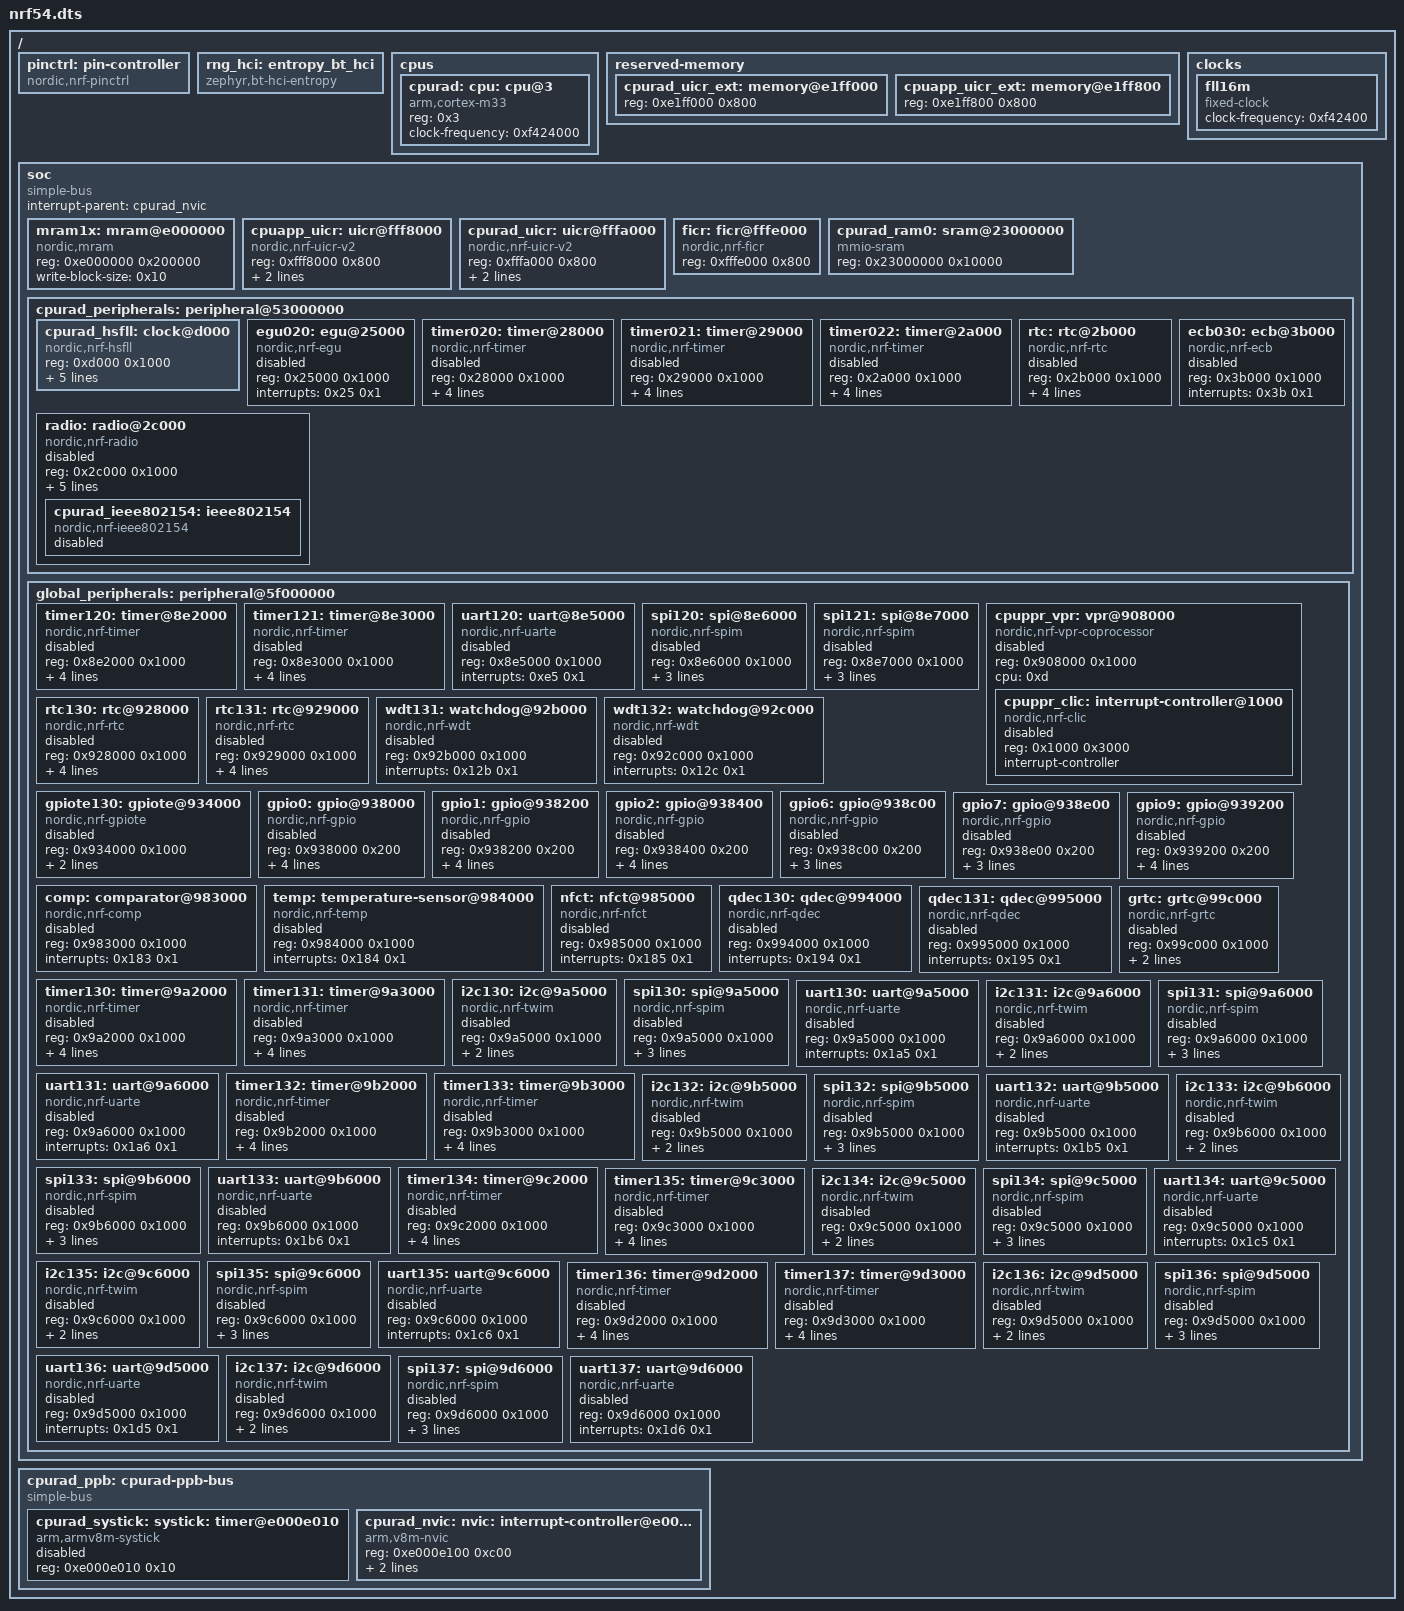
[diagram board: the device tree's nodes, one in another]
/dts-v1/;

/ {
	#address-cells = < 0x1 >;
	#size-cells = < 0x1 >;
	pinctrl: pin-controller {
		compatible = "nordic,nrf-pinctrl";
	};
	rng_hci: entropy_bt_hci {
		compatible = "zephyr,bt-hci-entropy";
		status = "okay";
	};
	cpus {
		#address-cells = < 0x1 >;
		#size-cells = < 0x0 >;
		cpurad: cpu: cpu@3 {
			compatible = "arm,cortex-m33";
			reg = < 0x3 >;
			device_type = "cpu";
			clock-frequency = < 0xf424000 >;
		};
	};
	reserved-memory {
		#address-cells = < 0x1 >;
		#size-cells = < 0x1 >;
		cpurad_uicr_ext: memory@e1ff000 {
			reg = < 0xe1ff000 0x800 >;
			phandle = < 0x3 >;
		};
		cpuapp_uicr_ext: memory@e1ff800 {
			reg = < 0xe1ff800 0x800 >;
			phandle = < 0x2 >;
		};
	};
	clocks {
		fll16m: fll16m {
			compatible = "fixed-clock";
			#clock-cells = < 0x0 >;
			clock-frequency = < 0xf42400 >;
			phandle = < 0x4 >;
		};
	};
	soc {
		#address-cells = < 0x1 >;
		#size-cells = < 0x1 >;
		compatible = "simple-bus";
		interrupt-parent = < &cpurad_nvic >;
		ranges;
		mram1x: mram@e000000 {
			compatible = "nordic,mram";
			reg = < 0xe000000 0x200000 >;
			write-block-size = < 0x10 >;
		};
		cpuapp_uicr: uicr@fff8000 {
			compatible = "nordic,nrf-uicr-v2";
			reg = < 0xfff8000 0x800 >;
			domain = < 0x2 >;
			ptr-ext-uicr = < &cpuapp_uicr_ext >;
		};
		cpurad_uicr: uicr@fffa000 {
			compatible = "nordic,nrf-uicr-v2";
			reg = < 0xfffa000 0x800 >;
			domain = < 0x3 >;
			ptr-ext-uicr = < &cpurad_uicr_ext >;
		};
		ficr: ficr@fffe000 {
			compatible = "nordic,nrf-ficr";
			reg = < 0xfffe000 0x800 >;
			#nordic,ficr-cells = < 0x1 >;
			phandle = < 0x5 >;
		};
		cpurad_ram0: sram@23000000 {
			compatible = "mmio-sram";
			reg = < 0x23000000 0x10000 >;
			#address-cells = < 0x1 >;
			#size-cells = < 0x1 >;
			ranges = < 0x0 0x23000000 0x10000 >;
		};
		cpurad_peripherals: peripheral@53000000 {
			#address-cells = < 0x1 >;
			#size-cells = < 0x1 >;
			ranges = < 0x0 0x53000000 0x1000000 >;
			cpurad_hsfll: clock@d000 {
				compatible = "nordic,nrf-hsfll";
				#clock-cells = < 0x0 >;
				reg = < 0xd000 0x1000 >;
				clocks = < &fll16m >;
				clock-frequency = < 0xf424000 >;
				nordic,ficrs = < &ficr 0x418 >, < &ficr 0x420 >, < &ficr 0x438 >;
				nordic,ficr-names = "vsup", "coarse", "fine";
			};
			egu020: egu@25000 {
				compatible = "nordic,nrf-egu";
				reg = < 0x25000 0x1000 >;
				status = "disabled";
				interrupts = < 0x25 0x1 >;
			};
			timer020: timer@28000 {
				compatible = "nordic,nrf-timer";
				reg = < 0x28000 0x1000 >;
				status = "disabled";
				cc-num = < 0x8 >;
				interrupts = < 0x28 0x1 >;
				max-bit-width = < 0x20 >;
				prescaler = < 0x0 >;
			};
			timer021: timer@29000 {
				compatible = "nordic,nrf-timer";
				reg = < 0x29000 0x1000 >;
				status = "disabled";
				cc-num = < 0x8 >;
				interrupts = < 0x29 0x1 >;
				max-bit-width = < 0x20 >;
				prescaler = < 0x0 >;
			};
			timer022: timer@2a000 {
				compatible = "nordic,nrf-timer";
				reg = < 0x2a000 0x1000 >;
				status = "disabled";
				cc-num = < 0x8 >;
				interrupts = < 0x2a 0x1 >;
				max-bit-width = < 0x20 >;
				prescaler = < 0x0 >;
			};
			rtc: rtc@2b000 {
				compatible = "nordic,nrf-rtc";
				reg = < 0x2b000 0x1000 >;
				status = "disabled";
				cc-num = < 0x4 >;
				clock-frequency = < 0x8000 >;
				interrupts = < 0x2b 0x1 >;
				prescaler = < 0x1 >;
			};
			radio: radio@2c000 {
				compatible = "nordic,nrf-radio";
				reg = < 0x2c000 0x1000 >;
				status = "disabled";
				ble-2mbps-supported;
				ble-coded-phy-supported;
				dfe-supported;
				ieee802154-supported;
				interrupts = < 0x2c 0x1 >;
				cpurad_ieee802154: ieee802154 {
					compatible = "nordic,nrf-ieee802154";
					status = "disabled";
				};
			};
			ecb030: ecb@3b000 {
				compatible = "nordic,nrf-ecb";
				reg = < 0x3b000 0x1000 >;
				interrupts = < 0x3b 0x1 >;
				status = "disabled";
			};
		};
		global_peripherals: peripheral@5f000000 {
			#address-cells = < 0x1 >;
			#size-cells = < 0x1 >;
			ranges = < 0x0 0x5f000000 0x1000000 >;
			timer120: timer@8e2000 {
				compatible = "nordic,nrf-timer";
				reg = < 0x8e2000 0x1000 >;
				status = "disabled";
				cc-num = < 0x6 >;
				interrupts = < 0xe2 0x1 >;
				max-bit-width = < 0x20 >;
				prescaler = < 0x0 >;
			};
			timer121: timer@8e3000 {
				compatible = "nordic,nrf-timer";
				reg = < 0x8e3000 0x1000 >;
				status = "disabled";
				cc-num = < 0x6 >;
				interrupts = < 0xe3 0x1 >;
				max-bit-width = < 0x20 >;
				prescaler = < 0x0 >;
			};
			uart120: uart@8e5000 {
				compatible = "nordic,nrf-uarte";
				reg = < 0x8e5000 0x1000 >;
				status = "disabled";
				interrupts = < 0xe5 0x1 >;
			};
			spi120: spi@8e6000 {
				compatible = "nordic,nrf-spim";
				reg = < 0x8e6000 0x1000 >;
				status = "disabled";
				easydma-maxcnt-bits = < 0xf >;
				interrupts = < 0xe6 0x1 >;
				max-frequency = < 0x1e84800 >;
				#address-cells = < 0x1 >;
				#size-cells = < 0x0 >;
			};
			spi121: spi@8e7000 {
				compatible = "nordic,nrf-spim";
				reg = < 0x8e7000 0x1000 >;
				status = "disabled";
				easydma-maxcnt-bits = < 0xf >;
				interrupts = < 0xe7 0x1 >;
				max-frequency = < 0x1e84800 >;
				#address-cells = < 0x1 >;
				#size-cells = < 0x0 >;
			};
			cpuppr_vpr: vpr@908000 {
				compatible = "nordic,nrf-vpr-coprocessor";
				reg = < 0x908000 0x1000 >;
				status = "disabled";
				cpu = < 0xd >;
				#address-cells = < 0x1 >;
				#size-cells = < 0x1 >;
				ranges = < 0x0 0x908000 0x4000 >;
				cpuppr_clic: interrupt-controller@1000 {
					compatible = "nordic,nrf-clic";
					reg = < 0x1000 0x3000 >;
					status = "disabled";
					#interrupt-cells = < 0x2 >;
					interrupt-controller;
					#address-cells = < 0x1 >;
				};
			};
			rtc130: rtc@928000 {
				compatible = "nordic,nrf-rtc";
				reg = < 0x928000 0x1000 >;
				status = "disabled";
				cc-num = < 0x4 >;
				clock-frequency = < 0x8000 >;
				interrupts = < 0x128 0x1 >;
				prescaler = < 0x1 >;
			};
			rtc131: rtc@929000 {
				compatible = "nordic,nrf-rtc";
				reg = < 0x929000 0x1000 >;
				status = "disabled";
				cc-num = < 0x4 >;
				clock-frequency = < 0x8000 >;
				interrupts = < 0x129 0x1 >;
				prescaler = < 0x1 >;
			};
			wdt131: watchdog@92b000 {
				compatible = "nordic,nrf-wdt";
				reg = < 0x92b000 0x1000 >;
				status = "disabled";
				interrupts = < 0x12b 0x1 >;
			};
			wdt132: watchdog@92c000 {
				compatible = "nordic,nrf-wdt";
				reg = < 0x92c000 0x1000 >;
				status = "disabled";
				interrupts = < 0x12c 0x1 >;
			};
			gpiote130: gpiote@934000 {
				compatible = "nordic,nrf-gpiote";
				reg = < 0x934000 0x1000 >;
				status = "disabled";
				instance = < 0x82 >;
				interrupts = < 0x69 0x1 >;
				phandle = < 0x6 >;
			};
			gpio0: gpio@938000 {
				compatible = "nordic,nrf-gpio";
				reg = < 0x938000 0x200 >;
				status = "disabled";
				#gpio-cells = < 0x2 >;
				gpio-controller;
				gpiote-instance = < &gpiote130 >;
				ngpios = < 0xc >;
				port = < 0x0 >;
			};
			gpio1: gpio@938200 {
				compatible = "nordic,nrf-gpio";
				reg = < 0x938200 0x200 >;
				status = "disabled";
				#gpio-cells = < 0x2 >;
				gpio-controller;
				gpiote-instance = < &gpiote130 >;
				ngpios = < 0xc >;
				port = < 0x1 >;
			};
			gpio2: gpio@938400 {
				compatible = "nordic,nrf-gpio";
				reg = < 0x938400 0x200 >;
				status = "disabled";
				#gpio-cells = < 0x2 >;
				gpio-controller;
				gpiote-instance = < &gpiote130 >;
				ngpios = < 0xc >;
				port = < 0x2 >;
			};
			gpio6: gpio@938c00 {
				compatible = "nordic,nrf-gpio";
				reg = < 0x938c00 0x200 >;
				status = "disabled";
				#gpio-cells = < 0x2 >;
				gpio-controller;
				ngpios = < 0xe >;
				port = < 0x6 >;
			};
			gpio7: gpio@938e00 {
				compatible = "nordic,nrf-gpio";
				reg = < 0x938e00 0x200 >;
				status = "disabled";
				#gpio-cells = < 0x2 >;
				gpio-controller;
				ngpios = < 0x8 >;
				port = < 0x7 >;
			};
			gpio9: gpio@939200 {
				compatible = "nordic,nrf-gpio";
				reg = < 0x939200 0x200 >;
				status = "disabled";
				#gpio-cells = < 0x2 >;
				gpio-controller;
				gpiote-instance = < &gpiote130 >;
				ngpios = < 0x6 >;
				port = < 0x9 >;
			};
			comp: comparator@983000 {
				compatible = "nordic,nrf-comp";
				reg = < 0x983000 0x1000 >;
				status = "disabled";
				interrupts = < 0x183 0x1 >;
				#io-channel-cells = < 0x1 >;
			};
			temp: temperature-sensor@984000 {
				compatible = "nordic,nrf-temp";
				reg = < 0x984000 0x1000 >;
				interrupts = < 0x184 0x1 >;
				status = "disabled";
			};
			nfct: nfct@985000 {
				compatible = "nordic,nrf-nfct";
				reg = < 0x985000 0x1000 >;
				status = "disabled";
				interrupts = < 0x185 0x1 >;
			};
			qdec130: qdec@994000 {
				compatible = "nordic,nrf-qdec";
				reg = < 0x994000 0x1000 >;
				status = "disabled";
				interrupts = < 0x194 0x1 >;
			};
			qdec131: qdec@995000 {
				compatible = "nordic,nrf-qdec";
				reg = < 0x995000 0x1000 >;
				status = "disabled";
				interrupts = < 0x195 0x1 >;
			};
			grtc: grtc@99c000 {
				compatible = "nordic,nrf-grtc";
				reg = < 0x99c000 0x1000 >;
				status = "disabled";
				cc-num = < 0x10 >;
				interrupts = < 0x6d 0x1 >;
			};
			timer130: timer@9a2000 {
				compatible = "nordic,nrf-timer";
				reg = < 0x9a2000 0x1000 >;
				status = "disabled";
				cc-num = < 0x6 >;
				interrupts = < 0x1a2 0x1 >;
				max-bit-width = < 0x20 >;
				prescaler = < 0x0 >;
			};
			timer131: timer@9a3000 {
				compatible = "nordic,nrf-timer";
				reg = < 0x9a3000 0x1000 >;
				status = "disabled";
				cc-num = < 0x6 >;
				interrupts = < 0x1a3 0x1 >;
				max-bit-width = < 0x20 >;
				prescaler = < 0x0 >;
			};
			i2c130: i2c@9a5000 {
				compatible = "nordic,nrf-twim";
				reg = < 0x9a5000 0x1000 >;
				status = "disabled";
				interrupts = < 0x1a5 0x1 >;
				easydma-maxcnt-bits = < 0xf >;
				#address-cells = < 0x1 >;
				#size-cells = < 0x0 >;
			};
			spi130: spi@9a5000 {
				compatible = "nordic,nrf-spim";
				reg = < 0x9a5000 0x1000 >;
				status = "disabled";
				easydma-maxcnt-bits = < 0xf >;
				interrupts = < 0x1a5 0x1 >;
				max-frequency = < 0x7a1200 >;
				#address-cells = < 0x1 >;
				#size-cells = < 0x0 >;
			};
			uart130: uart@9a5000 {
				compatible = "nordic,nrf-uarte";
				reg = < 0x9a5000 0x1000 >;
				status = "disabled";
				interrupts = < 0x1a5 0x1 >;
			};
			i2c131: i2c@9a6000 {
				compatible = "nordic,nrf-twim";
				reg = < 0x9a6000 0x1000 >;
				status = "disabled";
				interrupts = < 0x1a6 0x1 >;
				easydma-maxcnt-bits = < 0xf >;
				#address-cells = < 0x1 >;
				#size-cells = < 0x0 >;
			};
			spi131: spi@9a6000 {
				compatible = "nordic,nrf-spim";
				reg = < 0x9a6000 0x1000 >;
				status = "disabled";
				easydma-maxcnt-bits = < 0xf >;
				interrupts = < 0x1a6 0x1 >;
				max-frequency = < 0x7a1200 >;
				#address-cells = < 0x1 >;
				#size-cells = < 0x0 >;
			};
			uart131: uart@9a6000 {
				compatible = "nordic,nrf-uarte";
				reg = < 0x9a6000 0x1000 >;
				status = "disabled";
				interrupts = < 0x1a6 0x1 >;
			};
			timer132: timer@9b2000 {
				compatible = "nordic,nrf-timer";
				reg = < 0x9b2000 0x1000 >;
				status = "disabled";
				cc-num = < 0x6 >;
				interrupts = < 0x1b2 0x1 >;
				max-bit-width = < 0x20 >;
				prescaler = < 0x0 >;
			};
			timer133: timer@9b3000 {
				compatible = "nordic,nrf-timer";
				reg = < 0x9b3000 0x1000 >;
				status = "disabled";
				cc-num = < 0x6 >;
				interrupts = < 0x1b3 0x1 >;
				max-bit-width = < 0x20 >;
				prescaler = < 0x0 >;
			};
			i2c132: i2c@9b5000 {
				compatible = "nordic,nrf-twim";
				reg = < 0x9b5000 0x1000 >;
				status = "disabled";
				interrupts = < 0x1b5 0x1 >;
				easydma-maxcnt-bits = < 0xf >;
				#address-cells = < 0x1 >;
				#size-cells = < 0x0 >;
			};
			spi132: spi@9b5000 {
				compatible = "nordic,nrf-spim";
				reg = < 0x9b5000 0x1000 >;
				status = "disabled";
				easydma-maxcnt-bits = < 0xf >;
				interrupts = < 0x1b5 0x1 >;
				max-frequency = < 0x7a1200 >;
				#address-cells = < 0x1 >;
				#size-cells = < 0x0 >;
			};
			uart132: uart@9b5000 {
				compatible = "nordic,nrf-uarte";
				reg = < 0x9b5000 0x1000 >;
				status = "disabled";
				interrupts = < 0x1b5 0x1 >;
			};
			i2c133: i2c@9b6000 {
				compatible = "nordic,nrf-twim";
				reg = < 0x9b6000 0x1000 >;
				status = "disabled";
				interrupts = < 0x1b6 0x1 >;
				easydma-maxcnt-bits = < 0xf >;
				#address-cells = < 0x1 >;
				#size-cells = < 0x0 >;
			};
			spi133: spi@9b6000 {
				compatible = "nordic,nrf-spim";
				reg = < 0x9b6000 0x1000 >;
				status = "disabled";
				easydma-maxcnt-bits = < 0xf >;
				interrupts = < 0x1b6 0x1 >;
				max-frequency = < 0x7a1200 >;
				#address-cells = < 0x1 >;
				#size-cells = < 0x0 >;
			};
			uart133: uart@9b6000 {
				compatible = "nordic,nrf-uarte";
				reg = < 0x9b6000 0x1000 >;
				status = "disabled";
				interrupts = < 0x1b6 0x1 >;
			};
			timer134: timer@9c2000 {
				compatible = "nordic,nrf-timer";
				reg = < 0x9c2000 0x1000 >;
				status = "disabled";
				cc-num = < 0x6 >;
				interrupts = < 0x1c2 0x1 >;
				max-bit-width = < 0x20 >;
				prescaler = < 0x0 >;
			};
			timer135: timer@9c3000 {
				compatible = "nordic,nrf-timer";
				reg = < 0x9c3000 0x1000 >;
				status = "disabled";
				cc-num = < 0x6 >;
				interrupts = < 0x1c3 0x1 >;
				max-bit-width = < 0x20 >;
				prescaler = < 0x0 >;
			};
			i2c134: i2c@9c5000 {
				compatible = "nordic,nrf-twim";
				reg = < 0x9c5000 0x1000 >;
				status = "disabled";
				interrupts = < 0x1c5 0x1 >;
				easydma-maxcnt-bits = < 0xf >;
				#address-cells = < 0x1 >;
				#size-cells = < 0x0 >;
			};
			spi134: spi@9c5000 {
				compatible = "nordic,nrf-spim";
				reg = < 0x9c5000 0x1000 >;
				status = "disabled";
				easydma-maxcnt-bits = < 0xf >;
				interrupts = < 0x1c5 0x1 >;
				max-frequency = < 0x7a1200 >;
				#address-cells = < 0x1 >;
				#size-cells = < 0x0 >;
			};
			uart134: uart@9c5000 {
				compatible = "nordic,nrf-uarte";
				reg = < 0x9c5000 0x1000 >;
				status = "disabled";
				interrupts = < 0x1c5 0x1 >;
			};
			i2c135: i2c@9c6000 {
				compatible = "nordic,nrf-twim";
				reg = < 0x9c6000 0x1000 >;
				status = "disabled";
				interrupts = < 0x1c6 0x1 >;
				easydma-maxcnt-bits = < 0xf >;
				#address-cells = < 0x1 >;
				#size-cells = < 0x0 >;
			};
			spi135: spi@9c6000 {
				compatible = "nordic,nrf-spim";
				reg = < 0x9c6000 0x1000 >;
				status = "disabled";
				easydma-maxcnt-bits = < 0xf >;
				interrupts = < 0x1c6 0x1 >;
				max-frequency = < 0x7a1200 >;
				#address-cells = < 0x1 >;
				#size-cells = < 0x0 >;
			};
			uart135: uart@9c6000 {
				compatible = "nordic,nrf-uarte";
				reg = < 0x9c6000 0x1000 >;
				status = "disabled";
				interrupts = < 0x1c6 0x1 >;
			};
			timer136: timer@9d2000 {
				compatible = "nordic,nrf-timer";
				reg = < 0x9d2000 0x1000 >;
				status = "disabled";
				cc-num = < 0x6 >;
				interrupts = < 0x1d2 0x1 >;
				max-bit-width = < 0x20 >;
				prescaler = < 0x0 >;
			};
			timer137: timer@9d3000 {
				compatible = "nordic,nrf-timer";
				reg = < 0x9d3000 0x1000 >;
				status = "disabled";
				cc-num = < 0x6 >;
				interrupts = < 0x1d3 0x1 >;
				max-bit-width = < 0x20 >;
				prescaler = < 0x0 >;
			};
			i2c136: i2c@9d5000 {
				compatible = "nordic,nrf-twim";
				reg = < 0x9d5000 0x1000 >;
				status = "disabled";
				interrupts = < 0x1d5 0x1 >;
				easydma-maxcnt-bits = < 0xf >;
				#address-cells = < 0x1 >;
				#size-cells = < 0x0 >;
			};
			spi136: spi@9d5000 {
				compatible = "nordic,nrf-spim";
				reg = < 0x9d5000 0x1000 >;
				status = "disabled";
				easydma-maxcnt-bits = < 0xf >;
				interrupts = < 0x1d5 0x1 >;
				max-frequency = < 0x7a1200 >;
				#address-cells = < 0x1 >;
				#size-cells = < 0x0 >;
			};
			uart136: uart@9d5000 {
				compatible = "nordic,nrf-uarte";
				reg = < 0x9d5000 0x1000 >;
				status = "disabled";
				interrupts = < 0x1d5 0x1 >;
			};
			i2c137: i2c@9d6000 {
				compatible = "nordic,nrf-twim";
				reg = < 0x9d6000 0x1000 >;
				status = "disabled";
				interrupts = < 0x1d6 0x1 >;
				easydma-maxcnt-bits = < 0xf >;
				#address-cells = < 0x1 >;
				#size-cells = < 0x0 >;
			};
			spi137: spi@9d6000 {
				compatible = "nordic,nrf-spim";
				reg = < 0x9d6000 0x1000 >;
				status = "disabled";
				easydma-maxcnt-bits = < 0xf >;
				interrupts = < 0x1d6 0x1 >;
				max-frequency = < 0x7a1200 >;
				#address-cells = < 0x1 >;
				#size-cells = < 0x0 >;
			};
			uart137: uart@9d6000 {
				compatible = "nordic,nrf-uarte";
				reg = < 0x9d6000 0x1000 >;
				status = "disabled";
				interrupts = < 0x1d6 0x1 >;
			};
		};
	};
	cpurad_ppb: cpurad-ppb-bus {
		#address-cells = < 0x1 >;
		#size-cells = < 0x1 >;
		compatible = "simple-bus";
		ranges;
		cpurad_systick: systick: timer@e000e010 {
			compatible = "arm,armv8m-systick";
			reg = < 0xe000e010 0x10 >;
			status = "disabled";
		};
		cpurad_nvic: nvic: interrupt-controller@e000e100 {
			compatible = "arm,v8m-nvic";
			reg = < 0xe000e100 0xc00 >;
			arm,num-irq-priority-bits = < 0x3 >;
			#interrupt-cells = < 0x2 >;
			interrupt-controller;
			#address-cells = < 0x1 >;
			phandle = < 0x1 >;
		};
	};
};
